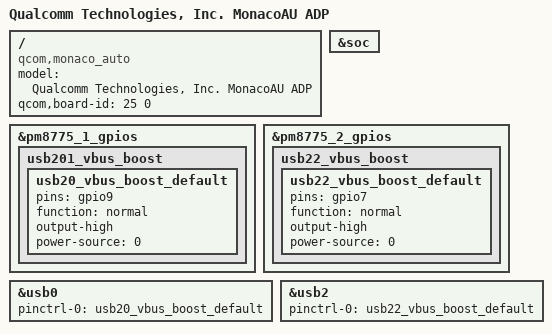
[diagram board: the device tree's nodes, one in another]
#include "monaco_auto-pmic-overlay.dtsi"

/ {
	model = "Qualcomm Technologies, Inc. MonacoAU ADP";
	compatible =  "qcom,monaco_auto", "qcom,adp";
	qcom,board-id = <25 0>;
};

&soc {
};

&pm8775_1_gpios {
	usb201_vbus_boost {
		usb20_vbus_boost_default: usb20_vbus_boost_default {
			pins = "gpio9";
			function = "normal";
			output-high;
			power-source = <0>;
		};
	};
};

&pm8775_2_gpios {
	usb22_vbus_boost {
		usb22_vbus_boost_default: usb22_vbus_boost_default {
			pins = "gpio7";
			function = "normal";
			output-high;
			power-source = <0>;
		};
	};
};

&usb0 {
	pinctrl-names = "default";
	pinctrl-0 = <&usb20_vbus_boost_default>;
};

&usb2 {
	pinctrl-names = "default";
	pinctrl-0 = <&usb22_vbus_boost_default>;
};
